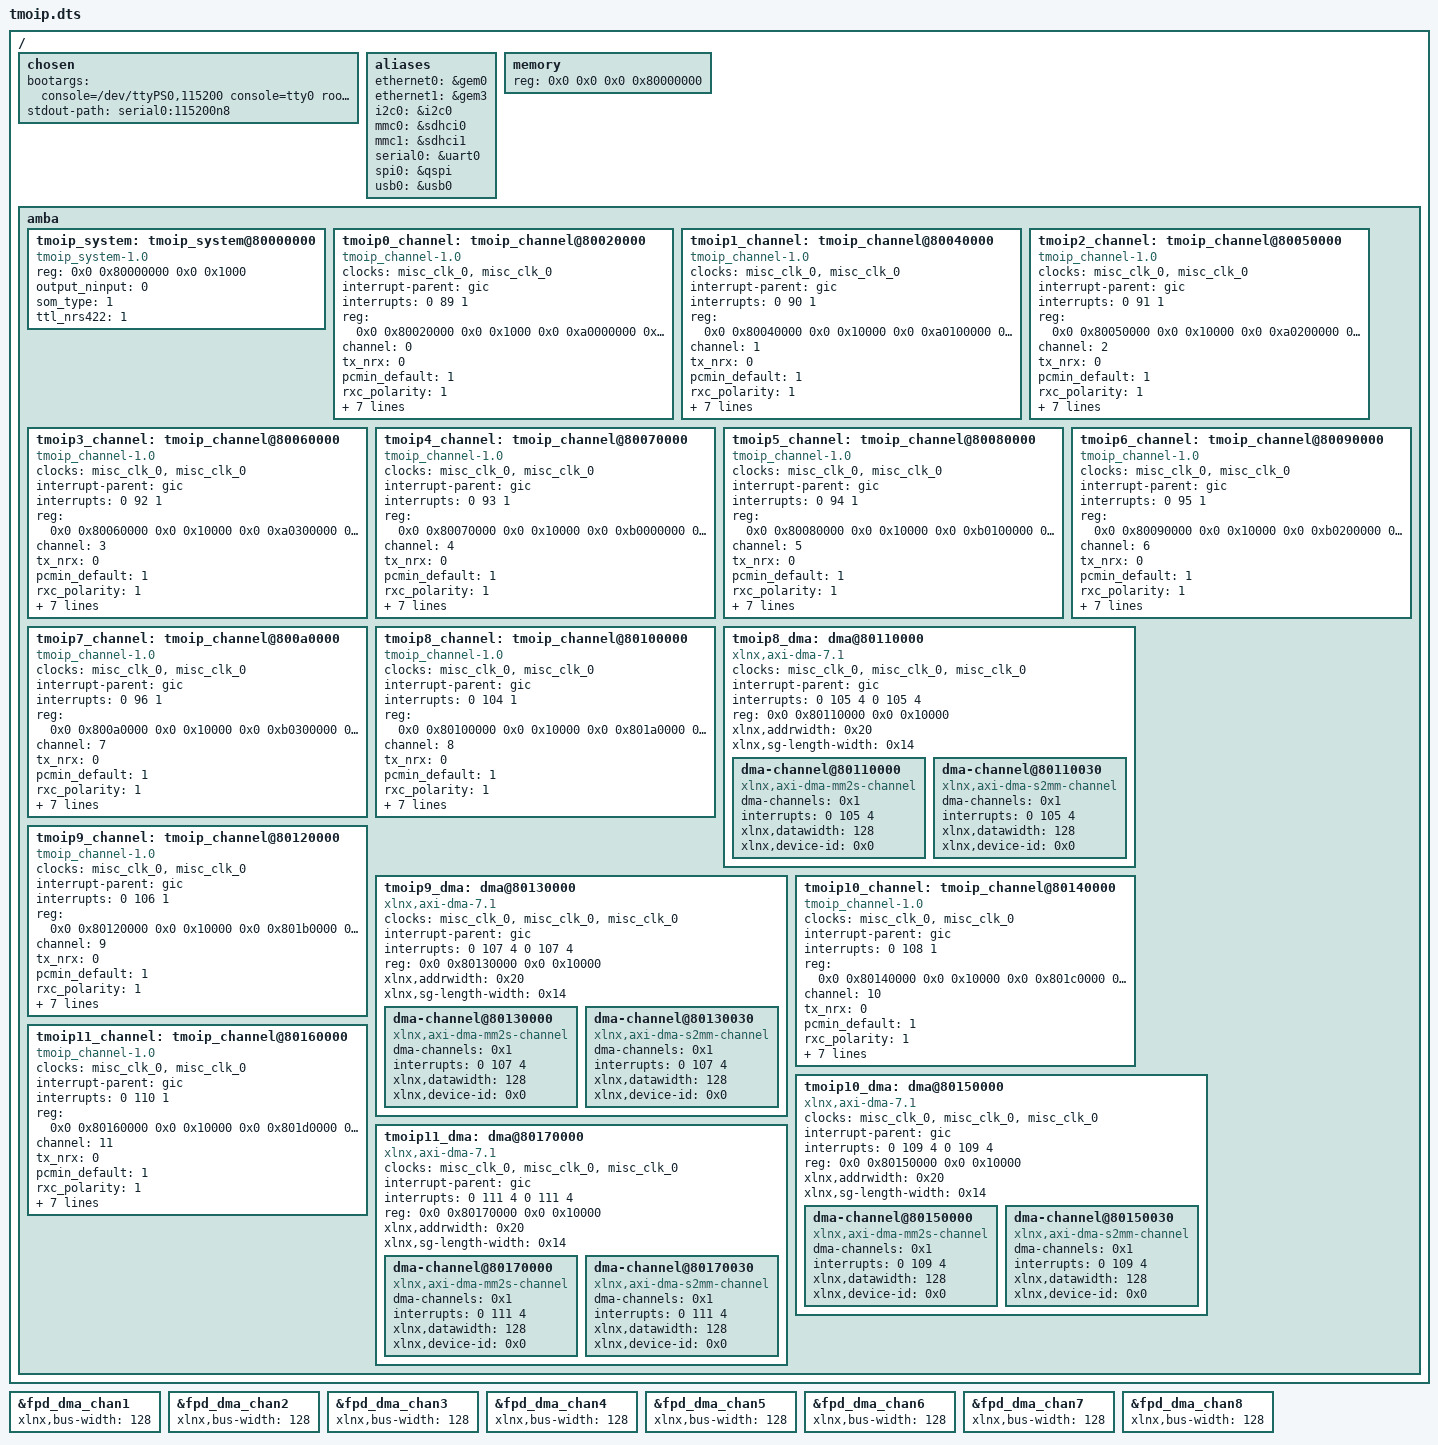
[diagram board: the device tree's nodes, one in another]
/*
 * CAUTION: This file is automatically generated by Xilinx.
 * Version: XSCT 2020.2
 * Today is: Fri Feb 19 11:42:01 2021
 */


/dts-v1/;
#include "zynqmp.dtsi"
#include "zynqmp-clk-ccf.dtsi"
#include "pl.dtsi"
#include "pcw.dtsi"
/ {
	chosen {
		bootargs = "console=/dev/ttyPS0,115200 console=tty0 root=/dev/mmcblk1p2 loglevel=7 rw earlyprintk earlycon audit=0 clk_ignore_unused mem=2048M"; 
		stdout-path = "serial0:115200n8";
	};
	aliases {
		ethernet0 = &gem0;
		ethernet1 = &gem3;
		i2c0 = &i2c0;
		mmc0 = &sdhci0;
	        mmc1 = &sdhci1;
		serial0 = &uart0;
		spi0 = &qspi;
		usb0 = &usb0;
	};
        /delete-node/ memory;
	memory {
		device_type = "memory";
		reg = <0x0 0x0 0x0 0x80000000>;
	};
	amba {
	   tmoip_system: tmoip_system@80000000 {
	            compatible = "tmoip_system-1.0";
		    reg = <0x0 0x80000000 0x0 0x1000>;
		    output_ninput = <0>;
		    som_type = <1>;
		    ttl_nrs422 = <1>;
	   };

	   tmoip0_channel: tmoip_channel@80020000 {
	            compatible = "tmoip_channel-1.0";
		    clock-names = "axi_lite_aclk", "axis_in_aclk";
		    clocks = <&misc_clk_0>, <&misc_clk_0>;
		    interrupt-parent = <&gic>;
		    interrupts = <0 89 1>;
		    reg = <0x0 0x80020000 0x0 0x1000 0x0 0xa0000000 0x0 0x100000>;
		    channel = <0>;
		    tx_nrx = <0>;
		    pcmin_default = <1>;
		    rxc_polarity = <1>;
		    rxd_polarity = <0>;
		    txc_polarity = <0>;
		    txd_polarity = <0>;
		    refclk_hz = <300000000>;
		    int_retry_cnt = <4500000>;
		    dma_type = <0>;
		    dmas = <&fpd_dma_chan1 0>;
		    dma-names = "dma";
	    };
		    
	    tmoip1_channel: tmoip_channel@80040000 {
	            compatible = "tmoip_channel-1.0";
		    clock-names = "axi_lite_aclk", "axis_in_aclk";
		    clocks = <&misc_clk_0>, <&misc_clk_0>;
		    interrupt-parent = <&gic>;
		    interrupts = <0 90 1>;
     		    reg = <0x0 0x80040000 0x0 0x10000 0x0 0xa0100000 0x0 0x100000>;
		    channel = <1>;
		    tx_nrx = <0>;
		    pcmin_default = <1>;
		    rxc_polarity = <1>;
		    rxd_polarity = <0>;
		    txc_polarity = <0>;
		    txd_polarity = <0>;
		    refclk_hz = <300000000>;
		    int_retry_cnt = <4500000>;
		    dma_type = <0>;
		    dmas = <&fpd_dma_chan2 0>;
		    dma-names = "dma";
	    };

            tmoip2_channel: tmoip_channel@80050000 {
	            compatible = "tmoip_channel-1.0";
		    clock-names = "axi_lite_aclk", "axis_in_aclk";
		    clocks = <&misc_clk_0>, <&misc_clk_0>;
		    interrupt-parent = <&gic>;
		    interrupts = <0 91 1>;
		    reg = <0x0 0x80050000 0x0 0x10000 0x0 0xa0200000 0x0 0x100000>;
		    channel = <2>;
		    tx_nrx = <0>;
		    pcmin_default = <1>;
		    rxc_polarity = <1>;
		    rxd_polarity = <0>;
		    txc_polarity = <0>;
		    txd_polarity = <0>;
		    refclk_hz = <300000000>;
		    int_retry_cnt = <4500000>;
		    dma_type = <0>;
		    dmas = <&fpd_dma_chan3 0>;
		    dma-names = "dma";
	    };

	      tmoip3_channel: tmoip_channel@80060000 {
	            compatible = "tmoip_channel-1.0";
		    clock-names = "axi_lite_aclk", "axis_in_aclk";
		    clocks = <&misc_clk_0>, <&misc_clk_0>;
		    interrupt-parent = <&gic>;
		    interrupts = <0 92 1>;
		    reg = <0x0 0x80060000 0x0 0x10000 0x0 0xa0300000 0x0 0x100000>;
		    channel = <3>;
		    tx_nrx = <0>;
		    pcmin_default = <1>;
		    rxc_polarity = <1>;
		    rxd_polarity = <0>;
		    txc_polarity = <0>;
		    txd_polarity = <0>;
		    refclk_hz = <300000000>;
		    int_retry_cnt = <4500000>;
		    dma_type = <0>;
		    dmas = <&fpd_dma_chan4 0>;
		    dma-names = "dma";
		};

	      tmoip4_channel: tmoip_channel@80070000 {
	            compatible = "tmoip_channel-1.0";
		    clock-names = "axi_lite_aclk", "axis_in_aclk";
		    clocks = <&misc_clk_0>, <&misc_clk_0>;
		    interrupt-parent = <&gic>;
		    interrupts = <0 93 1>;
		    reg = <0x0 0x80070000 0x0 0x10000 0x0 0xb0000000 0x0 0x100000>;
		    channel = <4>;
		    tx_nrx = <0>;
		    pcmin_default = <1>;
		    rxc_polarity = <1>;
		    rxd_polarity = <0>;
		    txc_polarity = <0>;
		    txd_polarity = <0>;
		    refclk_hz = <300000000>;
		    int_retry_cnt = <4500000>;
		    dma_type = <0>;
		    dmas = <&fpd_dma_chan5 0>;
		    dma-names = "dma";
		};

	      tmoip5_channel: tmoip_channel@80080000 {
	            compatible = "tmoip_channel-1.0";
		    clock-names = "axi_lite_aclk", "axis_in_aclk";
		    clocks = <&misc_clk_0>, <&misc_clk_0>;
		    interrupt-parent = <&gic>;
		    interrupts = <0 94 1>;
		    reg = <0x0 0x80080000 0x0 0x10000 0x0 0xb0100000 0x0 0x100000>;
		    channel = <5>;
		    tx_nrx = <0>;
		    pcmin_default = <1>;
		    rxc_polarity = <1>;
		    rxd_polarity = <0>;
		    txc_polarity = <0>;
		    txd_polarity = <0>;
		    refclk_hz = <300000000>;
		    int_retry_cnt = <4500000>;
		    dma_type = <0>;
		    dmas = <&fpd_dma_chan6 0>;
		    dma-names = "dma";
		};

	      tmoip6_channel: tmoip_channel@80090000 {
	            compatible = "tmoip_channel-1.0";
		    clock-names = "axi_lite_aclk", "axis_in_aclk";
		    clocks = <&misc_clk_0>, <&misc_clk_0>;
		    interrupt-parent = <&gic>;
		    interrupts = <0 95 1>;
		    reg = <0x0 0x80090000 0x0 0x10000 0x0 0xb0200000 0x0 0x100000>;
		    channel = <6>;
		    tx_nrx = <0>;
		    pcmin_default = <1>;
		    rxc_polarity = <1>;
		    rxd_polarity = <0>;
		    txc_polarity = <0>;
		    txd_polarity = <0>;
		    refclk_hz = <300000000>;
		    int_retry_cnt = <4500000>;
		    dma_type = <0>;
		    dmas = <&fpd_dma_chan7 0>;
		    dma-names = "dma";
		};

	      tmoip7_channel: tmoip_channel@800a0000 {
	            compatible = "tmoip_channel-1.0";
		    clock-names = "axi_lite_aclk", "axis_in_aclk";
		    clocks = <&misc_clk_0>, <&misc_clk_0>;
		    interrupt-parent = <&gic>;
		    interrupts = <0 96 1>;
		    reg = <0x0 0x800a0000 0x0 0x10000 0x0 0xb0300000 0x0 0x100000>;
		    channel = <7>;
		    tx_nrx = <0>;
		    pcmin_default = <1>;
		    rxc_polarity = <1>;
		    rxd_polarity = <0>;
		    txc_polarity = <0>;
		    txd_polarity = <0>;
		    refclk_hz = <300000000>;
		    int_retry_cnt = <4500000>;
		    dma_type = <0>;
		    dmas = <&fpd_dma_chan8 0>;
		    dma-names = "dma";
		};
		
	      tmoip8_channel: tmoip_channel@80100000 {
	            compatible = "tmoip_channel-1.0";
		    clock-names = "axi_lite_aclk", "axis_in_aclk";
		    clocks = <&misc_clk_0>, <&misc_clk_0>;
		    interrupt-parent = <&gic>;
		    interrupts = <0 104 1>;
		    reg = <0x0 0x80100000 0x0 0x10000 0x0 0x801a0000 0x0 0x10000>;
		    channel = <8>;
		    tx_nrx = <0>;
		    pcmin_default = <1>;
		    rxc_polarity = <1>;
		    rxd_polarity = <0>;
		    txc_polarity = <0>;
		    txd_polarity = <0>;
		    refclk_hz = <300000000>;
		    int_retry_cnt = <4500000>;
		    dma_type = <1>;
		    dmas = <&tmoip8_dma 0>, <&tmoip8_dma 1>;
	            dma-names = "dmaout", "dmain";
		};
		tmoip8_dma: dma@80110000 {
			compatible = "xlnx,axi-dma-7.1", "xlnx,axi-dma-1.00.a";
	     		#dma-cells = <1>;
			clock-names = "s_axi_lite_aclk", "m_axi_mm2s_aclk", "m_axi_s2mm_aclk";
			clocks = <&misc_clk_0>, <&misc_clk_0>, <&misc_clk_0>;
			interrupt-names = "mm2s_introut", "s2mm_introut";
			interrupt-parent = <&gic>;
			interrupts = <0 105 4 0 105 4>;
			reg = <0x0 0x80110000 0x0 0x10000>;
			xlnx,addrwidth = <0x20>;
			xlnx,sg-length-width = <0x14>;
			dma-channel@80110000 {
				compatible = "xlnx,axi-dma-mm2s-channel";
				dma-channels = <0x1>;
				interrupts = <0 105 4>;
				xlnx,datawidth = <128>;
				xlnx,device-id = <0x0>;
			};
			dma-channel@80110030 {
				compatible = "xlnx,axi-dma-s2mm-channel";
				dma-channels = <0x1>;
				interrupts = <0 105 4>;
				xlnx,datawidth = <128>;
				xlnx,device-id = <0x0>;
			};
	       };

	      tmoip9_channel: tmoip_channel@80120000 {
	            compatible = "tmoip_channel-1.0";
		    clock-names = "axi_lite_aclk", "axis_in_aclk";
		    clocks = <&misc_clk_0>, <&misc_clk_0>;
		    interrupt-parent = <&gic>;
		    interrupts = <0 106 1>;
		    reg = <0x0 0x80120000 0x0 0x10000 0x0 0x801b0000 0x0 0x10000>;
		    channel = <9>;
		    tx_nrx = <0>;
		    pcmin_default = <1>;
		    rxc_polarity = <1>;
		    rxd_polarity = <0>;
		    txc_polarity = <0>;
		    txd_polarity = <0>;
		    refclk_hz = <300000000>;
		    int_retry_cnt = <4500000>;
		    dma_type = <1>;
		    dmas = <&tmoip9_dma 0>, <&tmoip9_dma 1>;
	            dma-names = "dmaout", "dmain";
		};
		tmoip9_dma: dma@80130000 {
			compatible = "xlnx,axi-dma-7.1", "xlnx,axi-dma-1.00.a";
	     		#dma-cells = <1>;
			clock-names = "s_axi_lite_aclk", "m_axi_mm2s_aclk", "m_axi_s2mm_aclk";
			clocks = <&misc_clk_0>, <&misc_clk_0>, <&misc_clk_0>;
			interrupt-names = "mm2s_introut", "s2mm_introut";
			interrupt-parent = <&gic>;
			interrupts = <0 107 4 0 107 4>;
			reg = <0x0 0x80130000 0x0 0x10000>;
			xlnx,addrwidth = <0x20>;
			xlnx,sg-length-width = <0x14>;
			dma-channel@80130000 {
				compatible = "xlnx,axi-dma-mm2s-channel";
				dma-channels = <0x1>;
				interrupts = <0 107 4>;
				xlnx,datawidth = <128>;
				xlnx,device-id = <0x0>;
			};
			dma-channel@80130030 {
				compatible = "xlnx,axi-dma-s2mm-channel";
				dma-channels = <0x1>;
				interrupts = <0 107 4>;
				xlnx,datawidth = <128>;
				xlnx,device-id = <0x0>;
			};
	       };
	      tmoip10_channel: tmoip_channel@80140000 {
	            compatible = "tmoip_channel-1.0";
		    clock-names = "axi_lite_aclk", "axis_in_aclk";
		    clocks = <&misc_clk_0>, <&misc_clk_0>;
		    interrupt-parent = <&gic>;
		    interrupts = <0 108 1>;
		    reg = <0x0 0x80140000 0x0 0x10000 0x0 0x801c0000 0x0 0x10000>;
		    channel = <10>;
		    tx_nrx = <0>;
		    pcmin_default = <1>;
		    rxc_polarity = <1>;
		    rxd_polarity = <0>;
		    txc_polarity = <0>;
		    txd_polarity = <0>;
		    refclk_hz = <300000000>;
		    int_retry_cnt = <4500000>;
		    dma_type = <1>;
		    dmas = <&tmoip10_dma 0>, <&tmoip10_dma 1>;
	            dma-names = "dmaout", "dmain";
		};
		tmoip10_dma: dma@80150000 {
			compatible = "xlnx,axi-dma-7.1", "xlnx,axi-dma-1.00.a";
	     		#dma-cells = <1>;
			clock-names = "s_axi_lite_aclk", "m_axi_mm2s_aclk", "m_axi_s2mm_aclk";
			clocks = <&misc_clk_0>, <&misc_clk_0>, <&misc_clk_0>;
			interrupt-names = "mm2s_introut", "s2mm_introut";
			interrupt-parent = <&gic>;
			interrupts = <0 109 4 0 109 4>;
			reg = <0x0 0x80150000 0x0 0x10000>;
			xlnx,addrwidth = <0x20>;
			xlnx,sg-length-width = <0x14>;
			dma-channel@80150000 {
				compatible = "xlnx,axi-dma-mm2s-channel";
				dma-channels = <0x1>;
				interrupts = <0 109 4>;
				xlnx,datawidth = <128>;
				xlnx,device-id = <0x0>;
			};
			dma-channel@80150030 {
				compatible = "xlnx,axi-dma-s2mm-channel";
				dma-channels = <0x1>;
				interrupts = <0 109 4>;
				xlnx,datawidth = <128>;
				xlnx,device-id = <0x0>;
			};
	       };
	      tmoip11_channel: tmoip_channel@80160000 {
	            compatible = "tmoip_channel-1.0";
		    clock-names = "axi_lite_aclk", "axis_in_aclk";
		    clocks = <&misc_clk_0>, <&misc_clk_0>;
		    interrupt-parent = <&gic>;
		    interrupts = <0 110 1>;
		    reg = <0x0 0x80160000 0x0 0x10000 0x0 0x801d0000 0x0 0x10000>;
		    channel = <11>;
		    tx_nrx = <0>;
		    pcmin_default = <1>;
		    rxc_polarity = <1>;
		    rxd_polarity = <0>;
		    txc_polarity = <0>;
		    txd_polarity = <0>;
		    refclk_hz = <300000000>;
		    int_retry_cnt = <4500000>;
		    dma_type = <1>;
		    dmas = <&tmoip11_dma 0>, <&tmoip11_dma 1>;
	            dma-names = "dmaout", "dmain";
		};
		tmoip11_dma: dma@80170000 {
			compatible = "xlnx,axi-dma-7.1", "xlnx,axi-dma-1.00.a";
	     		#dma-cells = <1>;
			clock-names = "s_axi_lite_aclk", "m_axi_mm2s_aclk", "m_axi_s2mm_aclk";
			clocks = <&misc_clk_0>, <&misc_clk_0>, <&misc_clk_0>;
			interrupt-names = "mm2s_introut", "s2mm_introut";
			interrupt-parent = <&gic>;
			interrupts = <0 111 4 0 111 4>;
			reg = <0x0 0x80170000 0x0 0x10000>;
			xlnx,addrwidth = <0x20>;
			xlnx,sg-length-width = <0x14>;
			dma-channel@80170000 {
				compatible = "xlnx,axi-dma-mm2s-channel";
				dma-channels = <0x1>;
				interrupts = <0 111 4>;
				xlnx,datawidth = <128>;
				xlnx,device-id = <0x0>;
			};
			dma-channel@80170030 {
				compatible = "xlnx,axi-dma-s2mm-channel";
				dma-channels = <0x1>;
				interrupts = <0 111 4>;
				xlnx,datawidth = <128>;
				xlnx,device-id = <0x0>;
			};
	       };
	};
};

&fpd_dma_chan1 {
	status = "okay";
	#dma-cells = <1>;
	xlnx,bus-width = <128>;
};
&fpd_dma_chan2 {
	status = "okay";
	#dma-cells = <1>;
	xlnx,bus-width = <128>;
};
&fpd_dma_chan3 {
	status = "okay";
	#dma-cells = <1>;
	xlnx,bus-width = <128>;
};
&fpd_dma_chan4 {
	status = "okay";
	#dma-cells = <1>;
	xlnx,bus-width = <128>;
};
&fpd_dma_chan5 {
	status = "okay";
	#dma-cells = <1>;
	xlnx,bus-width = <128>;
};
&fpd_dma_chan6 {
	status = "okay";
	#dma-cells = <1>;
	xlnx,bus-width = <128>;
};
&fpd_dma_chan7 {
	status = "okay";
	#dma-cells = <1>;
	xlnx,bus-width = <128>;
};
&fpd_dma_chan8 {
	status = "okay";
	#dma-cells = <1>;
	xlnx,bus-width = <128>;
};
